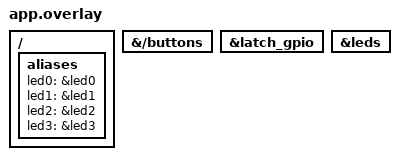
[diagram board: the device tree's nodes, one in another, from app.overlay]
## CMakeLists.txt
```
cmake_minimum_required(VERSION 3.20.0)

find_package(Zephyr REQUIRED HINTS $ENV{ZEPHYR_BASE})
project(04_key_control_led)

target_sources(app PRIVATE 
    src/main.c
    src/key_thread.c
    src/led_thread.c
)

target_include_directories(app PRIVATE 
    include
)
```

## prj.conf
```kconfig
CONFIG_GPIO=y
CONFIG_MEMC=y
CONFIG_MEMC_STM32=y
```

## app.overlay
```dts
/*
 * Enable the Armfly board LEDs. They are driven through an FMC-connected
 * memory-mapped latch, not direct STM32 GPIO pins.
 */

/ {
	aliases {
		led0 = &led0;
		led1 = &led1;
		led2 = &led2;
		led3 = &led3;
	};
};

&{/buttons} {
	/delete-property/ polling-mode;
};

&latch_gpio {
	status = "okay";
};

&leds {
	status = "okay";
};
```

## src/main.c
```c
/*
 * Copyright (c) 2012-2014 Wind River Systems, Inc.
 *
 * SPDX-License-Identifier: Apache-2.0
 */

#include <stdio.h>
#include <zephyr/app_version.h>
#include <zephyr/kernel.h>

int main(void)
{
	/*
	 * key_thread 和 led_thread 都通过 K_THREAD_DEFINE() 自动创建。
	 * main() 这里只负责打印启动信息，实际按键和 LED 逻辑在线程中运行。
	 */
	printk("04_key_control_led example start\r\n");
	printk("App version: %s\r\n", APP_VERSION_STRING);

	return 0;
}
```

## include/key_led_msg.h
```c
#ifndef KEY_LED_MSG_H
#define KEY_LED_MSG_H

#include <stdint.h>
#include <zephyr/kernel.h>

/* LED 线程支持的控制命令。 */
enum led_cmd_type {
	LED_CMD_OFF,
	LED_CMD_ON,
};

/*
 * 按键线程发送给 LED 线程的消息。
 *
 * led_id 对应 leds[] 数组下标：
 * - 0 表示 led0
 * - 1 表示 led1
 * 以此类推。
 */
struct led_msg {
	uint8_t led_id;
	enum led_cmd_type cmd;
};

/*
 * 消息队列在 led_thread.c 中用 K_MSGQ_DEFINE() 定义。
 * 这里用 extern 声明，让 key_thread.c 也可以访问同一个队列。
 */
extern struct k_msgq led_msgq;

#endif
```

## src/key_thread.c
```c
#include <stdbool.h>

#include <zephyr/app_version.h>
#include <zephyr/drivers/gpio.h>
#include <zephyr/kernel.h>
#include <zephyr/sys/printk.h>
#include <zephyr/sys/util.h>

#include "key_led_msg.h"

/*
 * 从设备树 alias 中取得按键 GPIO 配置。
 *
 * 例如 KEY_SPEC(sw0) 会先通过 DT_ALIAS(sw0) 找到 sw0 指向的节点，
 * 再读取这个节点的 gpios 属性，生成 struct gpio_dt_spec。
 */
#define KEY_SPEC(alias) GPIO_DT_SPEC_GET(DT_ALIAS(alias), gpios)

/* 取得设备树节点名称，用来打印按键名字。 */
#define KEY_NAME(alias) DT_NODE_FULL_NAME(DT_ALIAS(alias))

#define KEY_THREAD_STACK_SIZE 1024
#define KEY_THREAD_PRIORITY 5

/* 保存所有按键的 GPIO 信息，顺序要和 key_names[] 保持一致。 */
static const struct gpio_dt_spec keys[] = {
	KEY_SPEC(sw0),
	KEY_SPEC(sw1),
	KEY_SPEC(sw2),
	KEY_SPEC(sw3),
};

/* 每个按键对应的显示名称，用于 printk 输出。 */
static const char *const key_names[] = {
	KEY_NAME(sw0),
	KEY_NAME(sw1),
	KEY_NAME(sw2),
	KEY_NAME(sw3),
};

static struct k_work_delayable key_work;

/*
 * 已经确认稳定后的按键状态。
 *
 * 每个 bit 表示一个按键：bit=1 表示按下，bit=0 表示松开。
 */
static uint32_t stable_key_state;
static struct gpio_callback key_cb_data[ARRAY_SIZE(keys)];

static uint32_t read_key_state(void)
{
	uint32_t state = 0;

	for (size_t i = 0; i < ARRAY_SIZE(keys); i++) {
		/* gpio_pin_get_dt() 会考虑设备树里的 GPIO_ACTIVE_LOW/HIGH。 */
		int ret = gpio_pin_get_dt(&keys[i]);

		if (ret > 0) {
			state |= BIT(i);
		}
	}

	return state;
}

static void key_work_handler(struct k_work *work)
{
	uint32_t new_state;
	uint32_t changed;

	ARG_UNUSED(work);

	new_state = read_key_state();
	changed = new_state ^ stable_key_state;

	/* 没有变化说明可能只是抖动，不需要发送 LED 控制消息。 */
	if (changed == 0) {
		return;
	}

	for (size_t i = 0; i < ARRAY_SIZE(keys); i++) {
		if ((changed & BIT(i)) == 0) {
			continue;
		}

		/*
		 * 按键线程不直接控制 LED，而是把命令放进消息队列。
		 * LED 线程收到消息后再操作 GPIO，这样两个线程职责更清楚。
		 */
		if ((new_state & BIT(i)) != 0) {
			struct led_msg msg = {
				.led_id = i,
				.cmd = LED_CMD_ON,
			};

			printk("%s pressed\r\n", key_names[i]);
			k_msgq_put(&led_msgq, &msg, K_NO_WAIT);
		} else {
			struct led_msg msg = {
				.led_id = i,
				.cmd = LED_CMD_OFF,
			};

			printk("%s released\r\n", key_names[i]);
			k_msgq_put(&led_msgq, &msg, K_NO_WAIT);
		}
	}

	stable_key_state = new_state;
}

static void key_isr(const struct device *dev, struct gpio_callback *cb,
		    uint32_t pins)
{
	ARG_UNUSED(dev);
	ARG_UNUSED(cb);
	ARG_UNUSED(pins);

	/*
	 * 按键机械触点会抖动，所以中断里不马上读取按键。
	 * 每次中断都把延迟 work 重新安排到 20 ms 后执行，
	 * 只有按键状态稳定下来后才会进入 key_work_handler()。
	 */
	k_work_reschedule(&key_work, K_MSEC(20));
}

void key_thread(void *p1, void *p2, void *p3)
{
	int ret;

	ARG_UNUSED(p1);
	ARG_UNUSED(p2);
	ARG_UNUSED(p3);

	/* 初始化每一个按键对应的 GPIO 引脚。 */
	for (size_t i = 0; i < ARRAY_SIZE(keys); i++) {
		/* 检查 GPIO 控制器是否已经初始化完成。 */
		if (!gpio_is_ready_dt(&keys[i])) {
			printk("KEY%u GPIO controller is not ready\r\n", i);
			return;
		}

		/* 将按键引脚配置为输入模式。 */
		ret = gpio_pin_configure_dt(&keys[i], GPIO_INPUT);
		if (ret < 0) {
			printk("Failed to configure %s: %d\r\n", key_names[i], ret);
			return;
		}
	}

	/* 准备延迟 work，并记录启动时的初始按键状态。 */
	k_work_init_delayable(&key_work, key_work_handler);
	stable_key_state = read_key_state();

	/* 注册 GPIO 中断回调函数。 */
	for (size_t i = 0; i < ARRAY_SIZE(keys); i++) {
		gpio_init_callback(&key_cb_data[i], key_isr, BIT(keys[i].pin));

		ret = gpio_add_callback(keys[i].port, &key_cb_data[i]);
		if (ret < 0) {
			printk("Failed to add callback for %s: %d\r\n", key_names[i], ret);
			return;
		}
	}

	/* 打开双边沿中断：按下和松开都会触发。 */
	for (size_t i = 0; i < ARRAY_SIZE(keys); i++) {
		ret = gpio_pin_interrupt_configure_dt(&keys[i], GPIO_INT_EDGE_BOTH);
		if (ret < 0) {
			printk("Failed to configure interrupt for %s: %d\r\n", key_names[i], ret);
			return;
		}
	}
}

/*
 * 定义并启动按键线程。
 *
 * 最后一个参数 0 表示系统启动后立即运行；如果填 K_MSEC(x)，
 * 就会延迟 x 毫秒再启动线程。
 */
K_THREAD_DEFINE(key_thread_id, KEY_THREAD_STACK_SIZE,
		key_thread, NULL, NULL, NULL,
		KEY_THREAD_PRIORITY, 0, 0);
```

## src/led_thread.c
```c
#include <stdbool.h>

#include <zephyr/app_version.h>
#include <zephyr/drivers/gpio.h>
#include <zephyr/kernel.h>
#include <zephyr/sys/printk.h>
#include <zephyr/sys/util.h>

#include "key_led_msg.h"

#define LED_THREAD_STACK_SIZE 1024
#define LED_THREAD_PRIORITY 5

/*
 * 从设备树 alias 中取得 LED GPIO 配置。
 *
 * app.overlay 或开发板 dts 中通常会定义 led0、led1 等 alias。
 */
#define LED_SPEC(alias) GPIO_DT_SPEC_GET(DT_ALIAS(alias), gpios)

/*
 * 保存所有 LED 的 GPIO 信息。
 *
 * struct gpio_dt_spec 里面包含：
 * - port：GPIO 控制器设备
 * - pin：GPIO 引脚编号
 * - dt_flags：设备树里的 GPIO 标志，例如 GPIO_ACTIVE_LOW
 */
static const struct gpio_dt_spec leds[] = {
	LED_SPEC(led0),
	LED_SPEC(led1),
	LED_SPEC(led2),
	LED_SPEC(led3),
};

static struct led_msg msg;

/*
 * 定义一个消息队列，用来在按键线程和 LED 线程之间传递命令。
 *
 * 参数含义：
 * - led_msgq：队列名字
 * - sizeof(struct led_msg)：每条消息的大小
 * - 8：队列最多缓存 8 条消息
 * - 4：队列内存按 4 字节对齐
 */
K_MSGQ_DEFINE(led_msgq, sizeof(struct led_msg), 8, 4);

void led_thread(void *p1, void *p2, void *p3)
{
	int ret;

	ARG_UNUSED(p1);
	ARG_UNUSED(p2);
	ARG_UNUSED(p3);

	/* 初始化每一个 LED 对应的 GPIO 引脚。 */
	for (size_t i = 0; i < ARRAY_SIZE(leds); i++) {
		/*
		 * gpio_is_ready_dt() 检查 GPIO 控制器是否已经初始化完成。
		 * 如果控制器没有 ready，后续配置或读写这个引脚都会失败。
		 */
		if (!gpio_is_ready_dt(&leds[i])) {
			printk("LED%u GPIO controller is not ready\r\n", i);
			return;
		}

		/*
		 * 将 LED 引脚配置为输出，并设置为“非激活”状态。
		 *
		 * GPIO_OUTPUT_INACTIVE 会结合设备树里的 GPIO_ACTIVE_LOW/
		 * GPIO_ACTIVE_HIGH 自动决定实际输出电平。因此这里表示
		 * “先让 LED 熄灭”，而不是固定输出高电平或低电平。
		 */
		ret = gpio_pin_configure_dt(&leds[i], GPIO_OUTPUT_INACTIVE);
		if (ret < 0) {
			printk("Failed to configure LED%u: %d\r\n", i, ret);
			return;
		}
	}

	while (1) {
		/*
		 * K_FOREVER 表示如果队列为空，当前线程会一直等待。
		 * 等到按键线程放入消息后，这里才继续往下执行。
		 */
		k_msgq_get(&led_msgq, &msg, K_FOREVER);

		if (msg.led_id >= ARRAY_SIZE(leds)) {
			continue;
		}

		switch (msg.cmd) {
		case LED_CMD_ON:
			gpio_pin_set_dt(&leds[msg.led_id], 1);
			break;

		case LED_CMD_OFF:
			gpio_pin_set_dt(&leds[msg.led_id], 0);
			break;

		default:
			break;
		}
	}
}

/*
 * 定义并启动 LED 线程。
 *
 * 这个线程启动后会先初始化 LED，然后阻塞等待 led_msgq 中的消息。
 */
K_THREAD_DEFINE(led_thread_id, LED_THREAD_STACK_SIZE,
		led_thread, NULL, NULL, NULL,
		LED_THREAD_PRIORITY, 0, 0);
```
